# PIC32MK0512MCM100 register map
Vendor: Microchip
Registers are 32-bit, read-write, reset 0x0 unless marked. A register's access mark holds for its fields unless they carry their own. Addresses are absolute, and some are shared; only a register's first bit layout is shown; [hi:lo] are bit positions; {n}, {i} and the like mark numbered series.

## EEPROM
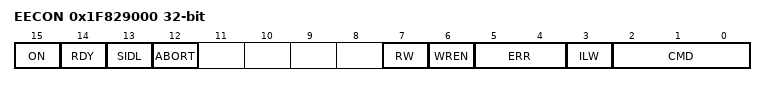
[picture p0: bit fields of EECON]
0x1F829000 EECON
  [15] ON, [14] RDY, [13] SIDL, [12] ABORT, [7] RW, [6] WREN, [5:4] ERR, [3] ILW, [2:0] CMD
0x1F829010 EEKEY wo
  [15:0] EEKEY
0x1F829020 EEADDR
  [13:0] EEADDR
0x1F829030 EEDATA

## MCPWMMODULE
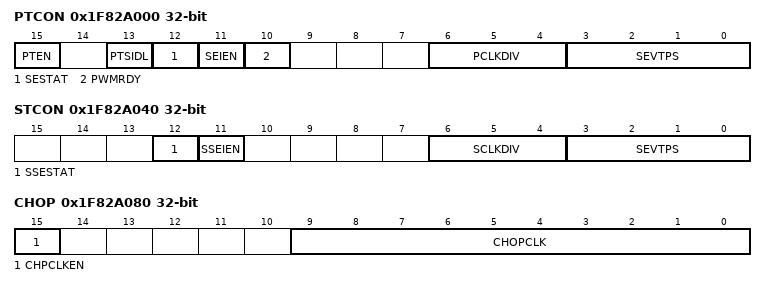
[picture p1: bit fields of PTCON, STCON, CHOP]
0x1F82A000 PTCON
  [15] PTEN, [13] PTSIDL, [12] SESTAT, [11] SEIEN, [10] PWMRDY, [6:4] PCLKDIV, [3:0] SEVTPS
0x1F82A010 PTPER
  [15:0] PTPER
0x1F82A020 SEVTCMP
  [15:0] SEVTCMP
0x1F82A030 PMTMR
  [15:0] PMTMR
0x1F82A040 STCON
  [12] SSESTAT, [11] SSEIEN, [6:4] SCLKDIV, [3:0] SEVTPS
0x1F82A050 STPER
  [15:0] STPER
0x1F82A060 SSEVTCMP
  [15:0] SSEVTCMP
0x1F82A070 SMTMR
  [15:0] SMTMR
0x1F82A080 CHOP
  [15] CHPCLKEN, [9:0] CHOPCLK
0x1F82A090 PWMKEY
  [15:0] PWMKEY

## MCPWMCHANNEL
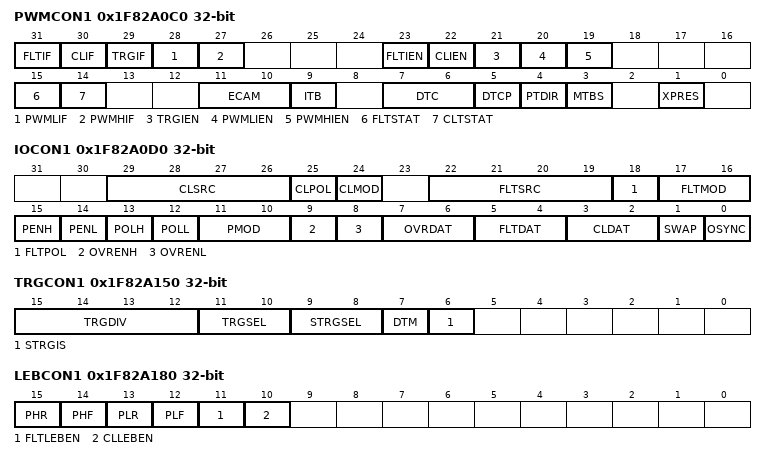
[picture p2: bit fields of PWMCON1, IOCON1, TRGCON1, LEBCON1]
0x1F82A0C0 PWMCON1
  [31] FLTIF, [30] CLIF, [29] TRGIF, [28] PWMLIF, [27] PWMHIF, [23] FLTIEN, [22] CLIEN, [21] TRGIEN, [20] PWMLIEN, [19] PWMHIEN, [15] FLTSTAT, [14] CLTSTAT, [11:10] ECAM, [9] ITB, [7:6] DTC, [5] DTCP, [4] PTDIR, [3] MTBS, [1] XPRES
0x1F82A0D0 IOCON1
  [29:26] CLSRC, [25] CLPOL, [24] CLMOD, [22:19] FLTSRC, [18] FLTPOL, [17:16] FLTMOD, [15] PENH, [14] PENL, [13] POLH, [12] POLL, [11:10] PMOD, [9] OVRENH, [8] OVRENL, [7:6] OVRDAT, [5:4] FLTDAT, [3:2] CLDAT, [1] SWAP, [0] OSYNC
0x1F82A0E0 PDC1
  [15:0] PDC
0x1F82A0F0 SDC1
  [15:0] SDC
0x1F82A100 PHASE1
  [15:0] PHASE
0x1F82A110 DTR1
  [15:0] DTR
0x1F82A120 ALTDTR1
  [15:0] ALTDTR
0x1F82A130 DTCOMP1
  [13:0] COMP
0x1F82A140 TRIG1
  [15:0] TRGCMP
0x1F82A150 TRGCON1
  [15:12] TRGDIV, [11:10] TRGSEL, [9:8] STRGSEL, [7] DTM, [6] STRGIS
0x1F82A160 STRIG1
  [15:0] STRGCMP
0x1F82A170 CAP1
  [15:0] CAP
0x1F82A180 LEBCON1
  [15] PHR, [14] PHF, [13] PLR, [12] PLF, [11] FLTLEBEN, [10] CLLEBEN
0x1F82A190 LEBDLY1
  [11:0] LEB
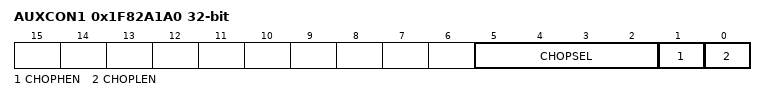
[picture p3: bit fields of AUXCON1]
0x1F82A1A0 AUXCON1
  [5:2] CHOPSEL, [1] CHOPHEN, [0] CHOPLEN
0x1F82A1B0 PTMR1
  [15:0] TMR

## pwm_mc_upb
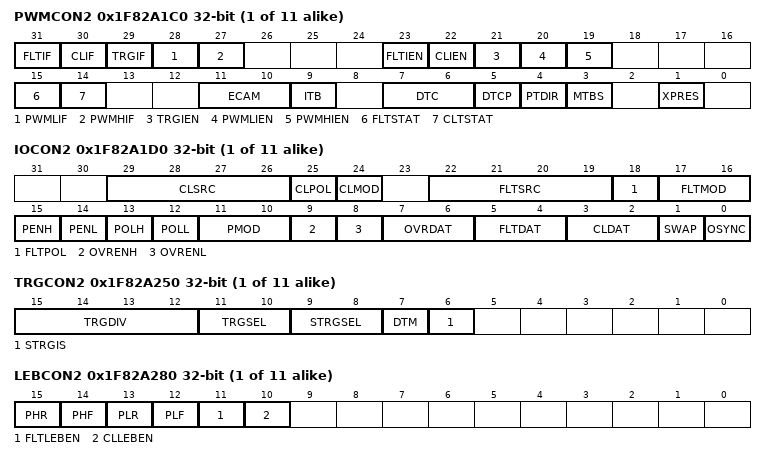
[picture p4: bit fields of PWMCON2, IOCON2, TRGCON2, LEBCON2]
{0x1F829FC0+0x100*i} PWMCON{i} (i=2..12)
  [31] FLTIF, [30] CLIF, [29] TRGIF, [28] PWMLIF, [27] PWMHIF, [23] FLTIEN, [22] CLIEN, [21] TRGIEN, [20] PWMLIEN, [19] PWMHIEN, [15] FLTSTAT, [14] CLTSTAT, [11:10] ECAM, [9] ITB, [7:6] DTC, [5] DTCP, [4] PTDIR, [3] MTBS, [1] XPRES
{0x1F829FD0+0x100*i} IOCON{i} (i=2..12)
  [29:26] CLSRC, [25] CLPOL, [24] CLMOD, [22:19] FLTSRC, [18] FLTPOL, [17:16] FLTMOD, [15] PENH, [14] PENL, [13] POLH, [12] POLL, [11:10] PMOD, [9] OVRENH, [8] OVRENL, [7:6] OVRDAT, [5:4] FLTDAT, [3:2] CLDAT, [1] SWAP, [0] OSYNC
{0x1F829FE0+0x100*i} PDC{i} (i=2..12)
  [15:0] PDC
{0x1F829FF0+0x100*i} SDC{i} (i=2..12)
  [15:0] SDC
{0x1F82A000+0x100*i} PHASE{i} (i=2..12)
  [15:0] PHASE
{0x1F82A010+0x100*i} DTR{i} (i=2..12)
  [15:0] DTR
{0x1F82A020+0x100*i} ALTDTR{i} (i=2..12)
  [15:0] ALTDTR
{0x1F82A030+0x100*i} DTCOMP{i} (i=2..12)
  [13:0] COMP
{0x1F82A040+0x100*i} TRIG{i} (i=2..12)
  [15:0] TRGCMP
{0x1F82A050+0x100*i} TRGCON{i} (i=2..12)
  [15:12] TRGDIV, [11:10] TRGSEL, [9:8] STRGSEL, [7] DTM, [6] STRGIS
{0x1F82A060+0x100*i} STRIG{i} (i=2..12)
  [15:0] STRGCMP
{0x1F82A070+0x100*i} CAP{i} (i=2..12)
  [15:0] CAP
{0x1F82A080+0x100*i} LEBCON{i} (i=2..12)
  [15] PHR, [14] PHF, [13] PLR, [12] PLF, [11] FLTLEBEN, [10] CLLEBEN
{0x1F82A090+0x100*i} LEBDLY{i} (i=2..12)
  [11:0] LEB
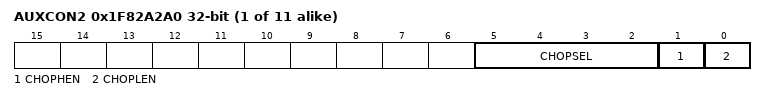
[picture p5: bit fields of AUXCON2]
{0x1F82A0A0+0x100*i} AUXCON{i} (i=2..12)
  [5:2] CHOPSEL, [1] CHOPHEN, [0] CHOPLEN
{0x1F82A0B0+0x100*i} PTMR{i} (i=2..12)
  [15:0] TMR

## qei
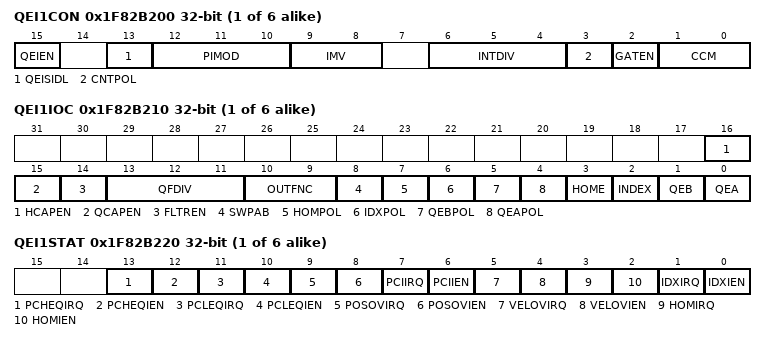
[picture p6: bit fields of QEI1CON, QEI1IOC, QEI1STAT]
{0x1F82B000+0x200*i} QEI{i}CON (i=1..6)
  [15] QEIEN, [13] QEISIDL, [12:10] PIMOD, [9:8] IMV, [6:4] INTDIV, [3] CNTPOL, [2] GATEN, [1:0] CCM
{0x1F82B010+0x200*i} QEI{i}IOC reset not defined (i=1..6) — (power-on value ---------------0000000000000xxxx)
  [16] HCAPEN, [15] QCAPEN, [14] FLTREN, [13:11] QFDIV, [10:9] OUTFNC, [8] SWPAB, [7] HOMPOL, [6] IDXPOL, [5] QEBPOL, [4] QEAPOL, [3] HOME ro, [2] INDEX ro, [1] QEB ro, [0] QEA ro
{0x1F82B020+0x200*i} QEI{i}STAT (i=1..6)
  [13] PCHEQIRQ, [12] PCHEQIEN, [11] PCLEQIRQ, [10] PCLEQIEN, [9] POSOVIRQ, [8] POSOVIEN, [7] PCIIRQ, [6] PCIIEN, [5] VELOVIRQ, [4] VELOVIEN, [3] HOMIRQ, [2] HOMIEN, [1] IDXIRQ, [0] IDXIEN
{0x1F82B030+0x200*i} POS{i}CNT (i=1..6)
  [31:0] POSCNT
{0x1F82B040+0x200*i} POS{i}HLD (i=1..6)
  [31:0] POSHLD
{0x1F82B050+0x200*i} VEL{i}CNT (i=1..6)
  [31:0] VELCNT
{0x1F82B060+0x200*i} VEL{i}HLD (i=1..6)
  [31:0] VELHLD
{0x1F82B070+0x200*i} INT{i}TMR (i=1..6)
  [31:0] INTTMR
{0x1F82B080+0x200*i} INT{i}HLD (i=1..6)
  [31:0] INTHLD
{0x1F82B090+0x200*i} INDX{i}CNT (i=1..6)
  [31:0] INDXCNT
{0x1F82B0A0+0x200*i} INDX{i}HLD (i=1..6)
  [31:0] INDXHLD
{0x1F82B0B0+0x200*i} QEI{i}ICC (i=1..6)
  [31:0] QEIICC
{0x1F82B0C0+0x200*i} QEI{i}CMPL (i=1..6)
  [31:0] QEICMPL
